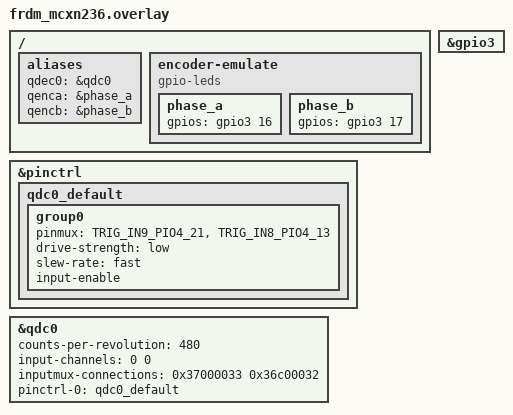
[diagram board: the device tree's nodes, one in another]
/*
 * Copyright 2026 NXP
 *
 * SPDX-License-Identifier: Apache-2.0
 */

#include <zephyr/dt-bindings/gpio/gpio.h>

/ {
	aliases {
		qdec0 = &qdc0;
		qenca = &phase_a;
		qencb = &phase_b;
	};

	encoder-emulate {
		compatible = "gpio-leds";

		phase_a: phase_a {
			gpios = <&gpio3 16 GPIO_ACTIVE_HIGH>;
		};

		phase_b: phase_b {
			gpios = <&gpio3 17 GPIO_ACTIVE_HIGH>;
		};
	};
};

&gpio3 {
	status = "okay";
};

/* Connect J3-5 -> J3-1, J3-7 -> J3-3 */
&pinctrl {
	qdc0_default: qdc0_default {
		group0 {
			pinmux = <TRIG_IN9_PIO4_21>,
				 <TRIG_IN8_PIO4_13>;
			drive-strength = "low";
			slew-rate = "fast";
			input-enable;
		};
	};
};

&qdc0 {
	status = "okay";
	counts-per-revolution = <480>;
	input-channels = <0 0>;
	inputmux-connections = <0x37000033 0x36c00032>;
	pinctrl-0 = <&qdc0_default>;
	pinctrl-names = "default";
};
